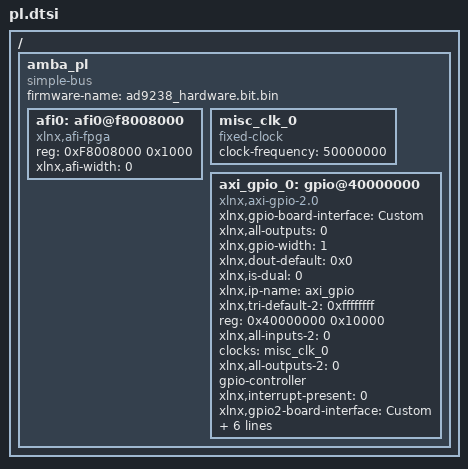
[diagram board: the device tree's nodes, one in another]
/ {
	amba_pl: amba_pl {
		ranges;
		compatible = "simple-bus";
		#address-cells = <1>;
		#size-cells = <1>;
		firmware-name = "ad9238_hardware.bit.bin";
		afi0: afi0@f8008000 {
			status = "okay";
			compatible = "xlnx,afi-fpga";
			#address-cells = <1>;
			reg = <0xF8008000 0x1000>;
			#size-cells = <0>;
			xlnx,afi-width = <0>;
		};
		misc_clk_0: misc_clk_0 {
			compatible = "fixed-clock";
			clock-frequency = <50000000>;
			#clock-cells = <0>;
		};
		axi_gpio_0: gpio@40000000 {
			xlnx,gpio-board-interface = "Custom";
			compatible = "xlnx,axi-gpio-2.0" , "xlnx,xps-gpio-1.00.a";
			xlnx,all-outputs = <0>;
			#gpio-cells = <2>;
			xlnx,gpio-width = <1>;
			xlnx,dout-default = <0x0>;
			xlnx,is-dual = <0>;
			xlnx,ip-name = "axi_gpio";
			xlnx,tri-default-2 = <0xffffffff>;
			reg = <0x40000000 0x10000>;
			xlnx,all-inputs-2 = <0>;
			clocks = <&misc_clk_0>;
			xlnx,all-outputs-2 = <0>;
			gpio-controller;
			xlnx,interrupt-present = <0>;
			xlnx,gpio2-board-interface = "Custom";
			xlnx,edk-iptype = "PERIPHERAL";
			xlnx,dout-default-2 = <0x0>;
			status = "okay";
			xlnx,gpio2-width = <32>;
			clock-names = "s_axi_aclk";
			xlnx,tri-default = <0x10>;
			xlnx,name = "axi_gpio_0";
			xlnx,all-inputs = <0>;
		};
	};
};
